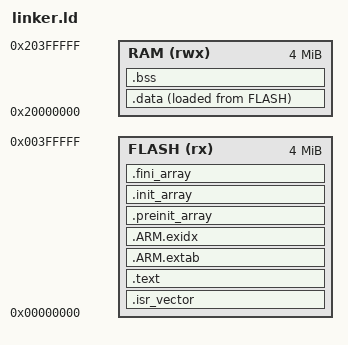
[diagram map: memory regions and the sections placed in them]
ENTRY(Reset_Handler)

MEMORY
{
    FLASH (rx)  : ORIGIN = 0x00000000, LENGTH = 4M
    RAM   (rwx) : ORIGIN = 0x20000000, LENGTH = 4M
}

_estack = ORIGIN(RAM) + LENGTH(RAM);
__stack_top = _estack;
__StackLimit = _estack - 0x4000;

SECTIONS
{
    .isr_vector :
    {
        KEEP(*(.isr_vector))
    } > FLASH

    .text :
    {
        *(.text.Reset_Handler)
        *(.text.Default_Handler)
        *(.text*)
        *(.rodata*)
        *(.glue_7)
        *(.glue_7t)
        KEEP(*(.init))
        KEEP(*(.fini))
    } > FLASH

    .ARM.extab :
    {
        *(.ARM.extab* .gnu.linkonce.armextab.*)
    } > FLASH

    .ARM.exidx :
    {
        __exidx_start = .;
        *(.ARM.exidx* .gnu.linkonce.armexidx.*)
        __exidx_end = .;
    } > FLASH

    .preinit_array :
    {
        PROVIDE_HIDDEN(__preinit_array_start = .);
        KEEP(*(.preinit_array*))
        PROVIDE_HIDDEN(__preinit_array_end = .);
    } > FLASH

    .init_array :
    {
        PROVIDE_HIDDEN(__init_array_start = .);
        KEEP(*(SORT_BY_INIT_PRIORITY(.init_array.*) SORT_BY_INIT_PRIORITY(.ctors.*)))
        KEEP(*(.init_array EXCLUDE_FILE (*crtbegin.o *crtbegin?.o *crtend.o *crtend?.o ) .ctors))
        PROVIDE_HIDDEN(__init_array_end = .);
    } > FLASH

    .fini_array :
    {
        PROVIDE_HIDDEN(__fini_array_start = .);
        KEEP(*(SORT_BY_INIT_PRIORITY(.fini_array.*) SORT_BY_INIT_PRIORITY(.dtors.*)))
        KEEP(*(.fini_array EXCLUDE_FILE (*crtbegin.o *crtbegin?.o *crtend.o *crtend?.o ) .dtors))
        PROVIDE_HIDDEN(__fini_array_end = .);
    } > FLASH

    _sidata = LOADADDR(.data);
    .data :
    {
        _sdata = .;
        *(.data*)
        _edata = .;
    } > RAM AT > FLASH

    .bss (NOLOAD) :
    {
        _sbss = .;
        *(.bss*)
        *(COMMON)
        _ebss = .;
    } > RAM

    . = ALIGN(8);
    __end__ = .;
    end = .;
}
